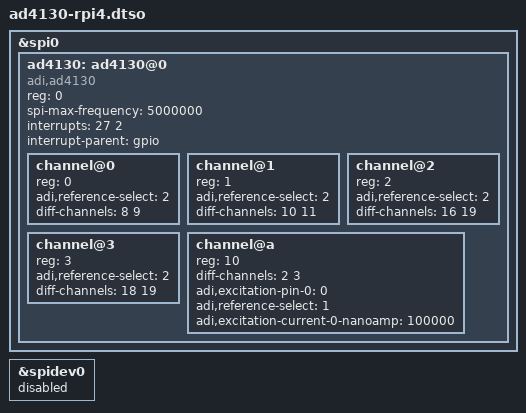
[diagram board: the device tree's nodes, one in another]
/dts-v1/;
/plugin/;
/ {
	fragment@0 {
		target = <&spi0>;
		__overlay__ {
			status = "okay";
			ad4130: ad4130@0 {
				compatible = "adi,ad4130";
				reg = <0>;
				#address-cells = <1>;
				#size-cells = <0>;
				spi-max-frequency = <5000000>;
				interrupts = <27 2>;
				interrupt-parent = <&gpio>;
				channel@0 {
					reg = <0>;
					adi,reference-select = <2>;
					diff-channels = <8 9>;
				};
				channel@1 {
					reg = <1>;
					adi,reference-select = <2>;
					diff-channels = <10 11>;
				};
				channel@2 {
					reg = <2>;
					adi,reference-select = <2>;
					diff-channels = <16 19>;
				};
				channel@3 {
					reg = <3>;
					adi,reference-select = <2>;
					diff-channels = <18 19>;
				};
				channel@a {
					reg = <10>;
					diff-channels = <2 3>;
					adi,excitation-pin-0 = <0>;
					adi,reference-select = <1>;
					adi,excitation-current-0-nanoamp = <100000>;
				};
			};
		};
	};
	fragment@1 {
		target = <&spidev0>;
		__overlay__ {
			status = "disabled";
		};
	};
};
